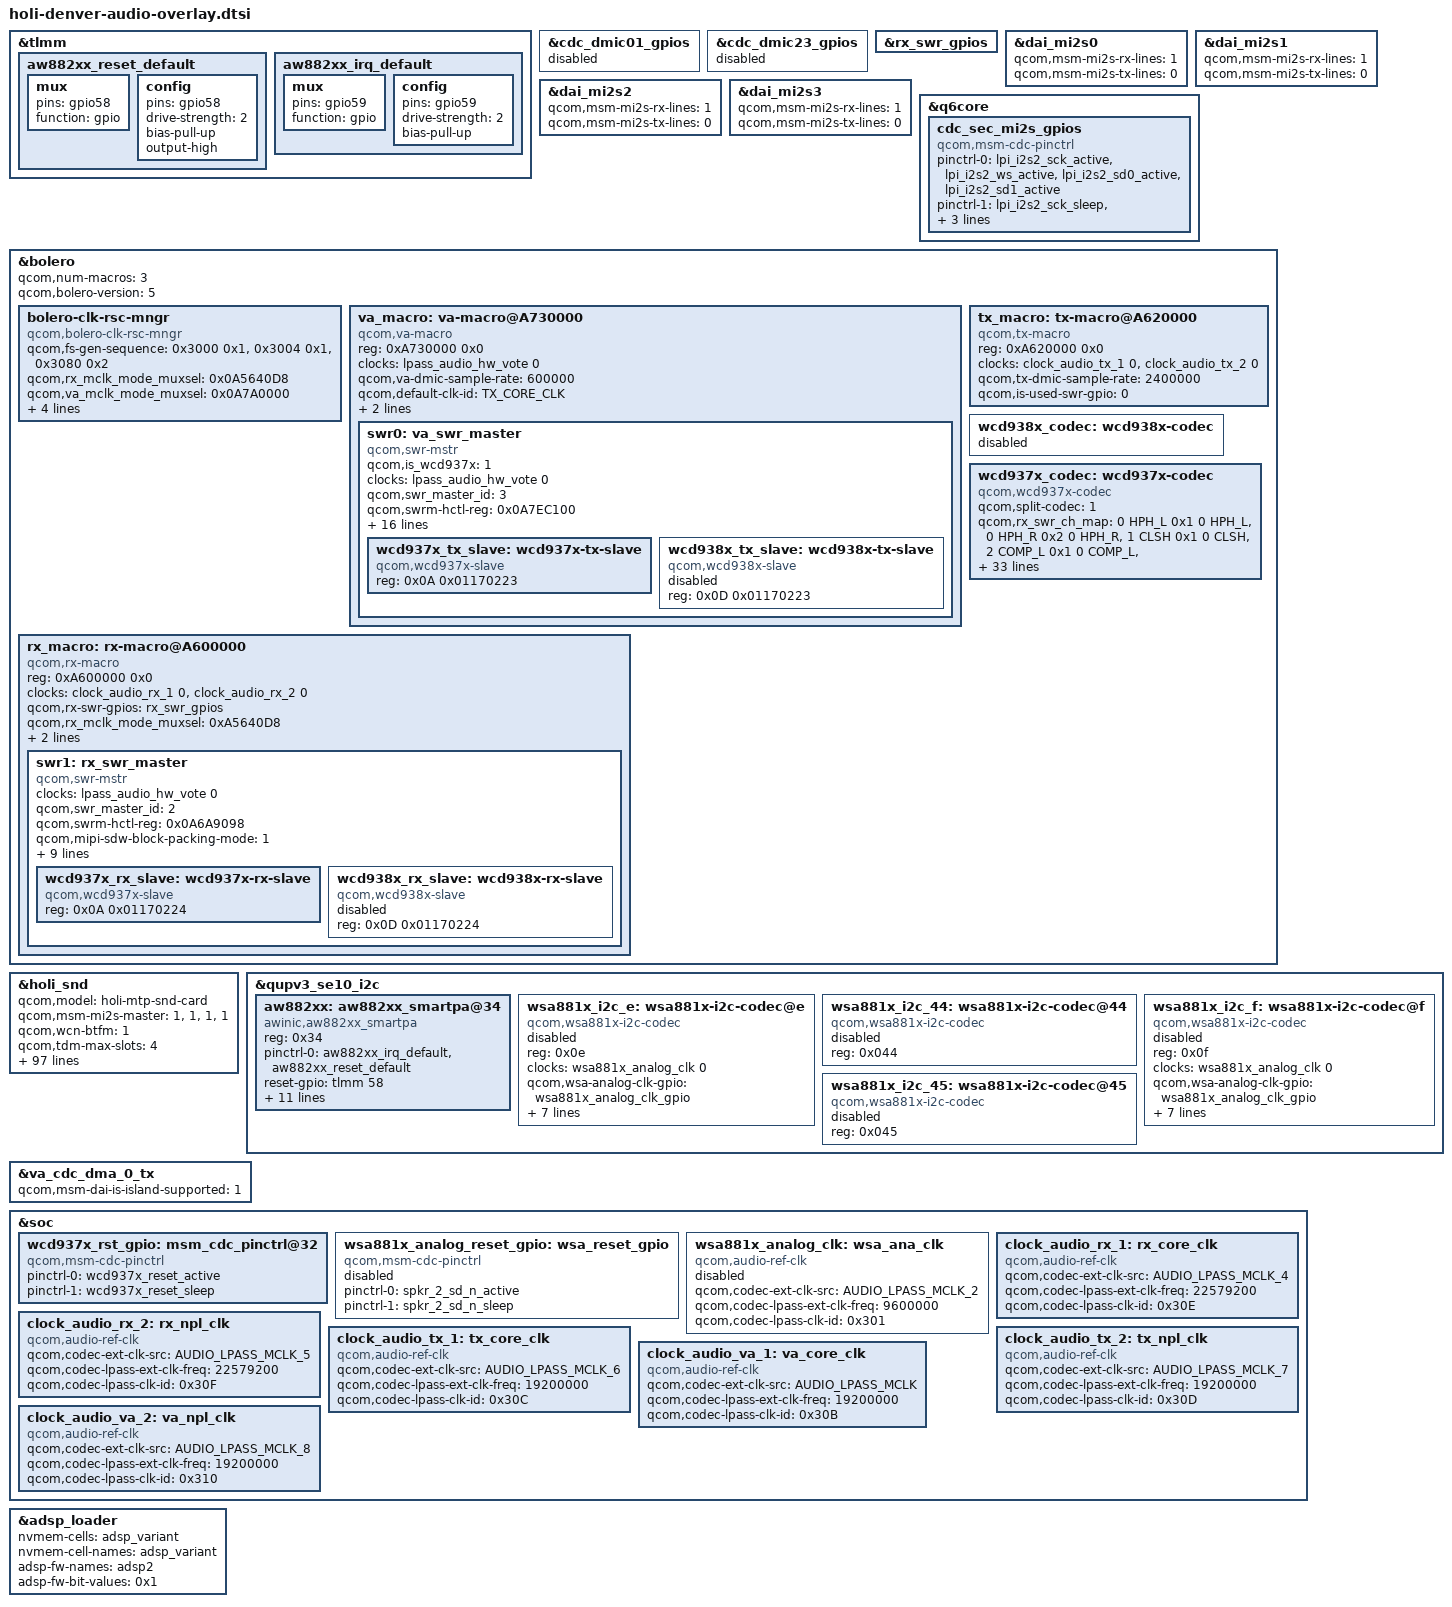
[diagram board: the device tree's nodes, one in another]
#include <dt-bindings/clock/qcom,audio-ext-clk.h>
#include <dt-bindings/sound/qcom,bolero-clk-rsc.h>
#include <dt-bindings/sound/audio-codec-port-types.h>
#include <dt-bindings/interrupt-controller/arm-gic.h>
#include <dt-bindings/gpio/gpio.h>

&tlmm{
	aw882xx_reset_default: aw882xx_reset_default {
		mux {
			pins = "gpio58";
			function = "gpio";
		};
		config {
			pins = "gpio58";
			drive-strength = <2>; /* 2 MA */
			bias-pull-up;
			output-high;
		};
	};

	aw882xx_irq_default: aw882xx_irq_default {
		mux {
			pins = "gpio59";
			function = "gpio";
		};
		config {
			pins = "gpio59";
			drive-strength = <2>; /* 2 MA */
			bias-pull-up;
		};
	};
};

&cdc_dmic01_gpios {
	status = "disabled";
};

&cdc_dmic23_gpios {
	status = "disabled";
};

&rx_swr_gpios {
	status = "okay";
};

&dai_mi2s0 {
	status = "okay";
	qcom,msm-mi2s-rx-lines = <1>;
	qcom,msm-mi2s-tx-lines = <0>;
};

&dai_mi2s1 {
	status = "okay";
	qcom,msm-mi2s-rx-lines = <1>;
	qcom,msm-mi2s-tx-lines = <0>;
};

&dai_mi2s2 {
	status = "okay";
	qcom,msm-mi2s-rx-lines = <1>;
	qcom,msm-mi2s-tx-lines = <0>;
};

&dai_mi2s3 {
	status = "okay";
	qcom,msm-mi2s-rx-lines = <1>;
	qcom,msm-mi2s-tx-lines = <0>;
};


&q6core {
   cdc_sec_mi2s_gpios: cdc_sec_mi2s_gpios {
           compatible = "qcom,msm-cdc-pinctrl";
           pinctrl-names = "aud_active", "aud_sleep";
           pinctrl-0 = <&lpi_i2s2_sck_active &lpi_i2s2_ws_active
                           &lpi_i2s2_sd0_active &lpi_i2s2_sd1_active>;
           pinctrl-1 = <&lpi_i2s2_sck_sleep &lpi_i2s2_ws_sleep
                           &lpi_i2s2_sd0_sleep &lpi_i2s2_sd1_sleep>;
           qcom,lpi-gpios;
   };
};

&bolero {
	qcom,num-macros = <3>;
	qcom,bolero-version = <5>;
	#address-cells = <1>;
	#size-cells = <1>;
	bolero-clk-rsc-mngr {
		compatible = "qcom,bolero-clk-rsc-mngr";
		qcom,fs-gen-sequence = <0x3000 0x1>,
					<0x3004 0x1>, <0x3080 0x2>;
	qcom,rx_mclk_mode_muxsel = <0x0A5640D8>;
	qcom,va_mclk_mode_muxsel = <0x0A7A0000>;
	clock-names = "tx_core_clk", "tx_npl_clk", "rx_core_clk", "rx_npl_clk",
		 "va_core_clk", "va_npl_clk";
	clocks = <&clock_audio_tx_1 0>, <&clock_audio_tx_2 0>,
		<&clock_audio_rx_1 0>, <&clock_audio_rx_2 0>,
		<&clock_audio_va_1 0>, <&clock_audio_va_2 0>;
	};

	va_macro: va-macro@A730000 {
		compatible = "qcom,va-macro";
		reg = <0xA730000 0x0>;
		clock-names = "lpass_audio_hw_vote";
		clocks = <&lpass_audio_hw_vote 0>;
		qcom,va-dmic-sample-rate = <600000>;
		qcom,default-clk-id = <TX_CORE_CLK>;
		qcom,is-used-swr-gpio = <1>;
		qcom,va-swr-gpios = <&va_swr_gpios>;
		swr0: va_swr_master {
			compatible = "qcom,swr-mstr";
			qcom,is_wcd937x = <1>;
			#address-cells = <2>;
			#size-cells = <0>;
			clock-names = "lpass_audio_hw_vote";
			clocks = <&lpass_audio_hw_vote 0>;
			qcom,swr_master_id = <3>;
			qcom,swrm-hctl-reg = <0x0A7EC100>;
			qcom,mipi-sdw-block-packing-mode = <1>;
			swrm-io-base = <0xA740000 0x0>;
			interrupts-extended =
				<&wakegic 5 IRQ_TYPE_LEVEL_HIGH>,
				<&tlmm 128 GPIO_ACTIVE_HIGH>;
			interrupt-names = "swr_master_irq", "swr_wake_irq";
			qcom,swr-num-ports = <3>;
			qcom,swr-port-mapping = <1 SWRM_TX1_CH1 0x1>,
				<1 SWRM_TX1_CH2 0x2>,
				<1 SWRM_TX1_CH3 0x4>, <1 SWRM_TX1_CH4 0x8>,
				<2 SWRM_TX2_CH1 0x1>, <2 SWRM_TX2_CH2 0x2>,
				<2 SWRM_TX2_CH3 0x4>, <2 SWRM_TX2_CH4 0x8>,
				<3 SWRM_TX3_CH1 0x1>, <3 SWRM_TX3_CH2 0x2>,
				<3 SWRM_TX3_CH3 0x4>, <3 SWRM_TX3_CH4 0x8>;
			qcom,swr-num-dev = <1>;
			qcom,swr-clock-stop-mode0 = <1>;
			qcom,swr-mstr-irq-wakeup-capable = <1>;
			wcd937x_tx_slave: wcd937x-tx-slave {
				compatible = "qcom,wcd937x-slave";
				reg = <0x0A 0x01170223>;
			};

			wcd938x_tx_slave: wcd938x-tx-slave {
				status = "disabled";
				compatible = "qcom,wcd938x-slave";
				reg = <0x0D 0x01170223>;
			};

		};
	};

	tx_macro: tx-macro@A620000 {
		compatible = "qcom,tx-macro";
		reg = <0xA620000 0x0>;
		clock-names = "tx_core_clk", "tx_npl_clk";
		clocks = <&clock_audio_tx_1 0>,
			 <&clock_audio_tx_2 0>;
		qcom,tx-dmic-sample-rate = <2400000>;
		qcom,is-used-swr-gpio = <0>;
	};

	rx_macro: rx-macro@A600000 {
		compatible = "qcom,rx-macro";
		reg = <0xA600000 0x0>;
		clock-names = "rx_core_clk", "rx_npl_clk";
		clocks = <&clock_audio_rx_1 0>,
			 <&clock_audio_rx_2 0>;
		qcom,rx-swr-gpios = <&rx_swr_gpios>;
		qcom,rx_mclk_mode_muxsel = <0xA5640D8>;
		qcom,rx-bcl-pmic-params = /bits/ 8 <0x00 0x03 0x48>;
		qcom,default-clk-id = <TX_CORE_CLK>;
		swr1: rx_swr_master {
			compatible = "qcom,swr-mstr";
			#address-cells = <2>;
			#size-cells = <0>;
			clock-names = "lpass_audio_hw_vote";
			clocks = <&lpass_audio_hw_vote 0>;
			qcom,swr_master_id = <2>;
			qcom,swrm-hctl-reg = <0x0A6A9098>;
			qcom,mipi-sdw-block-packing-mode = <1>;
			swrm-io-base = <0xA610000 0x0>;
			interrupts = <GIC_SPI 297 IRQ_TYPE_LEVEL_HIGH>;
			interrupt-names = "swr_master_irq";
			qcom,swr-num-ports = <6>;
			qcom,swr-port-mapping = <1 HPH_L 0x1>,
				<1 HPH_R 0x2>, <2 CLSH 0x1>,
				<3 COMP_L 0x1>, <3 COMP_R 0x2>,
				<4 LO 0x1>, <5 DSD_L 0x1>,
				<5 DSD_R 0x2>, <6 PCM_OUT1 0x01>;
			qcom,swr-num-dev = <1>;
			qcom,swr-clock-stop-mode0 = <1>;
			wcd937x_rx_slave: wcd937x-rx-slave {
				compatible = "qcom,wcd937x-slave";
				reg = <0x0A 0x01170224>;
			};

			wcd938x_rx_slave: wcd938x-rx-slave {
				status = "disabled";
				compatible = "qcom,wcd938x-slave";
				reg = <0x0D 0x01170224>;
			};
		};
	};

	wcd938x_codec: wcd938x-codec {
		status = "disabled";
	};

	wcd937x_codec: wcd937x-codec {
		compatible = "qcom,wcd937x-codec";
		qcom,split-codec = <1>;
		qcom,rx_swr_ch_map = <0 HPH_L 0x1 0 HPH_L>,
			<0 HPH_R 0x2 0 HPH_R>, <1 CLSH 0x1 0 CLSH>,
			<2 COMP_L 0x1 0 COMP_L>, <2 COMP_R 0x2 0 COMP_R>,
			<3 LO 0x1 0 LO>, <4 DSD_L 0x1 0 DSD_L>,
			<4 DSD_R 0x2 0 DSD_R>;
		qcom,tx_swr_ch_map = <0 ADC1 0x1 0 SWRM_TX1_CH1>,
			<1 ADC2 0x1 0 SWRM_TX2_CH1>,
			<1 ADC3 0x2 0 SWRM_TX2_CH2>,
			<2 DMIC0 0x1 0 SWRM_TX1_CH4>,
			<2 DMIC1 0x2 0 SWRM_TX2_CH1>,
			<2 MBHC 0x4 0 SWRM_TX2_CH2>,
			<3 DMIC2 0x1 0 SWRM_TX2_CH3>,
			<3 DMIC3 0x2 0 SWRM_TX2_CH4>,
			<3 DMIC4 0x4 0 SWRM_TX3_CH1>,
			<3 DMIC5 0x8 0 SWRM_TX3_CH2>;

		qcom,wcd-rst-gpio-node = <&wcd937x_rst_gpio>;
		qcom,rx-slave = <&wcd937x_rx_slave>;
		qcom,tx-slave = <&wcd937x_tx_slave>;

		cdc-vdd-rxtx-supply = <&L11A>;
		qcom,cdc-vdd-rxtx-voltage = <1800000 1800000>;
		qcom,cdc-vdd-rxtx-current = <30000>;

		cdc-vddpx-supply = <&L11A>;
		qcom,cdc-vddpx-voltage = <1800000 1800000>;
		qcom,cdc-vddpx-current = <30000>;

		cdc-vdd-buck-supply = <&L14A>;
		qcom,cdc-vdd-buck-voltage = <1800000 1800000>;
		qcom,cdc-vdd-buck-current = <650000>;

		cdc-vdd-mic-bias-supply = <&BOB>;
		qcom,cdc-vdd-mic-bias-voltage = <3296000 3296000>;
		qcom,cdc-vdd-mic-bias-current = <45000>;

		qcom,cdc-micbias1-mv = <1800>;
		qcom,cdc-micbias2-mv = <1800>;
		qcom,cdc-micbias3-mv = <1800>;

		qcom,cdc-static-supplies = "cdc-vdd-rxtx",
					   "cdc-vddpx",
					   "cdc-vdd-mic-bias";
		qcom,cdc-on-demand-supplies = "cdc-vdd-buck";
	};
};

&holi_snd {
	qcom,model = "holi-mtp-snd-card";
	qcom,msm-mi2s-master = <1>, <1>, <1>, <1>;
	qcom,wcn-btfm = <1>;
	qcom,tdm-max-slots = <4>;
	qcom,sec-mi2s-gpios = <&cdc_sec_mi2s_gpios>;

		asoc-platform = <&pcm0>, <&pcm1>, <&pcm2>, <&voip>, <&voice>,
				<&loopback>, <&compress>, <&hostless>,
				<&afe>, <&lsm>, <&routing>, <&compr>,
				<&pcm_noirq>;
		asoc-platform-names = "msm-pcm-dsp.0", "msm-pcm-dsp.1",
				"msm-pcm-dsp.2", "msm-voip-dsp",
				"msm-pcm-voice", "msm-pcm-loopback",
				"msm-compress-dsp", "msm-pcm-hostless",
				"msm-pcm-afe", "msm-lsm-client",
				"msm-pcm-routing", "msm-compr-dsp",
				"msm-pcm-dsp-noirq";
		asoc-cpu = <&dai_mi2s0>, <&dai_mi2s1>,
				<&dai_mi2s2>, <&dai_mi2s3>,
				<&dai_pri_auxpcm>,
				<&dai_sec_auxpcm>, <&dai_tert_auxpcm>,
				<&dai_quat_auxpcm>,
				<&afe_pcm_rx>, <&afe_pcm_tx>, <&afe_proxy_rx>,
				<&afe_proxy_tx>, <&incall_record_rx>,
				<&incall_record_tx>, <&incall_music_rx>,
				<&incall_music_2_rx>,
				<&afe_proxy_tx_1>,
				<&proxy_rx>, <&proxy_tx>,
				<&usb_audio_rx>, <&usb_audio_tx>,
				<&sb_7_rx>, <&sb_7_tx>, <&sb_8_tx>,
				<&dai_pri_tdm_rx_0>, <&dai_pri_tdm_tx_0>,
				<&dai_sec_tdm_rx_0>, <&dai_sec_tdm_tx_0>,
				<&dai_tert_tdm_rx_0>, <&dai_tert_tdm_tx_0>,
				<&dai_quat_tdm_rx_0>, <&dai_quat_tdm_tx_0>,
				<&va_cdc_dma_0_tx>, <&va_cdc_dma_1_tx>,
				<&va_cdc_dma_2_tx>,
				<&rx_cdc_dma_0_rx>, <&tx_cdc_dma_0_tx>,
				<&rx_cdc_dma_1_rx>, <&tx_cdc_dma_1_tx>,
				<&rx_cdc_dma_2_rx>, <&tx_cdc_dma_2_tx>,
				<&rx_cdc_dma_3_rx>, <&tx_cdc_dma_3_tx>,
				<&rx_cdc_dma_4_rx>, <&tx_cdc_dma_4_tx>,
				<&rx_cdc_dma_5_rx>, <&tx_cdc_dma_5_tx>,
				<&rx_cdc_dma_7_rx>,<&afe_loopback_tx>;
		asoc-cpu-names = "msm-dai-q6-mi2s.0", "msm-dai-q6-mi2s.1",
				"msm-dai-q6-mi2s.2", "msm-dai-q6-mi2s.3",
				"msm-dai-q6-auxpcm.1",
				"msm-dai-q6-auxpcm.2", "msm-dai-q6-auxpcm.3",
				"msm-dai-q6-auxpcm.4",
				"msm-dai-q6-dev.224",
				"msm-dai-q6-dev.225", "msm-dai-q6-dev.241",
				"msm-dai-q6-dev.240", "msm-dai-q6-dev.32771",
				"msm-dai-q6-dev.32772", "msm-dai-q6-dev.32773",
				"msm-dai-q6-dev.32770",
				"msm-dai-q6-dev.242",
				"msm-dai-q6-dev.8194", "msm-dai-q6-dev.8195",
				"msm-dai-q6-dev.28672", "msm-dai-q6-dev.28673",
				"msm-dai-q6-dev.16398", "msm-dai-q6-dev.16399",
				"msm-dai-q6-dev.16401",
				"msm-dai-q6-tdm.36864", "msm-dai-q6-tdm.36865",
				"msm-dai-q6-tdm.36880", "msm-dai-q6-tdm.36881",
				"msm-dai-q6-tdm.36896", "msm-dai-q6-tdm.36897",
				"msm-dai-q6-tdm.36912", "msm-dai-q6-tdm.36913",
				"msm-dai-cdc-dma-dev.45089",
				"msm-dai-cdc-dma-dev.45091",
				"msm-dai-cdc-dma-dev.45093",
				"msm-dai-cdc-dma-dev.45104",
				"msm-dai-cdc-dma-dev.45105",
				"msm-dai-cdc-dma-dev.45106",
				"msm-dai-cdc-dma-dev.45107",
				"msm-dai-cdc-dma-dev.45108",
				"msm-dai-cdc-dma-dev.45109",
				"msm-dai-cdc-dma-dev.45110",
				"msm-dai-cdc-dma-dev.45111",
				"msm-dai-cdc-dma-dev.45112",
				"msm-dai-cdc-dma-dev.45113",
				"msm-dai-cdc-dma-dev.45114",
				"msm-dai-cdc-dma-dev.45115",
				"msm-dai-cdc-dma-dev.45118",
				"msm-dai-q6-dev.24577";


	qcom,audio-routing =
		"AMIC1", "Analog Mic1",
		"Analog Mic1", "MIC BIAS1",
		"AMIC2", "Analog Mic2",
		"Analog Mic2", "MIC BIAS2",
		"AMIC3", "Analog Mic3",
		"Analog Mic3", "MIC BIAS3",
		"Analog Mic4", "MIC BIAS3",
		"TX DMIC0", "Digital Mic0",
		"TX DMIC0", "MIC BIAS1",
		"TX DMIC1", "Digital Mic1",
		"TX DMIC1", "MIC BIAS1",
		"TX DMIC2", "Digital Mic2",
		"TX DMIC2", "MIC BIAS3",
		"TX DMIC3", "Digital Mic3",
		"TX DMIC3", "MIC BIAS3",
		"IN1_HPHL", "HPHL_OUT",
		"IN2_HPHR", "HPHR_OUT",
		"IN3_AUX", "AUX_OUT",
		"RX_TX DEC0_INP", "TX DEC0 MUX",
		"RX_TX DEC1_INP", "TX DEC1 MUX",
		"RX_TX DEC2_INP", "TX DEC2 MUX",
		"RX_TX DEC3_INP", "TX DEC3 MUX",
		"TX SWR_INPUT", "WCD_TX_OUTPUT",
		"VA SWR_INPUT", "VA_SWR_CLK",
		"VA SWR_INPUT", "WCD_TX_OUTPUT",
		"VA_AIF1 CAP", "VA_SWR_CLK",
		"VA_AIF2 CAP", "VA_SWR_CLK",
		"VA_AIF3 CAP", "VA_SWR_CLK",
		"VA DMIC0", "Digital Mic0",
		"VA DMIC1", "Digital Mic1",
		"VA DMIC2", "Digital Mic2",
		"VA DMIC3", "Digital Mic3",
		"VA DMIC4", "Digital Mic4",
		"VA DMIC5", "Digital Mic5",
		"VA DMIC0", "VA MIC BIAS1",
		"VA DMIC1", "VA MIC BIAS1",
		"VA DMIC2", "VA MIC BIAS3",
		"VA DMIC3", "VA MIC BIAS3";
	qcom,msm-mbhc-hphl-swh = <1>;
	qcom,msm-mbhc-gnd-swh = <1>;
	asoc-codec  = <&stub_codec>, <&bolero>,
		      <&wcd937x_codec>,<&aw882xx>;
	asoc-codec-names = "msm-stub-codec.1", "bolero_codec",
			   "wcd937x_codec", "aw882xx_codec";
	qcom,msm_audio_ssr_devs = <&audio_apr>, <&q6core>, <&lpi_tlmm>,
				  <&bolero>;
};

&qupv3_se10_i2c {
        status = "ok";
        aw882xx: aw882xx_smartpa@34 {
			compatible = "awinic,aw882xx_smartpa";
			reg = <0x34>;
			pinctrl-names = "default";
			pinctrl-0 = <&aw882xx_irq_default>, <&aw882xx_reset_default>;
			reset-gpio = <&tlmm 58 0>;
			irq-gpio = <&tlmm 59 0x2008>;
			monitor-flag = <1>;
			monitor-timer-val = <3000>;
			afe-rx-portid = <0x1002>;
			afe-tx-portid = <0x1003>;
			low-vol-table-down = <3650 9 3 3750 9 2 3900 9 1>;
			low-vol-table-up = <4000 9 0 3800 9 1 3700 9 2>;
			low-temp-table-down = <0xFFFFFFFB 0x4 0x10 0xFFBEAE7E 0x0 0x5 0x9 0xFFD80505 0x5 0x6 0x6 0xFFED714D>;
			low-temp-table-up = <0x7 0x9 0x0 0x00000000 0x2 0x6 0x06 0xFFED714D 0xFFFFFFE 0x05 0x09 0xFFD80505>;
			status = "okay";
		};
		
	wsa881x_i2c_e: wsa881x-i2c-codec@e {
		status = "disabled";	
		compatible = "qcom,wsa881x-i2c-codec";
		reg = <0x0e>;
		clock-names = "wsa_mclk";
		clocks = <&wsa881x_analog_clk 0>;
		qcom,wsa-analog-clk-gpio = <&wsa881x_analog_clk_gpio>;
		qcom,wsa-analog-reset-gpio = <&wsa881x_analog_reset_gpio>;
		cdc-vdd-1p8-supply = <&L11A>;
		qcom,cdc-vdd-1p8-voltage = <1800000 1800000>;
		qcom,cdc-vdd-1p8-current = <10000>;
		qcom,cdc-static-supplies = "cdc-vdd-1p8";
		qcom,wsa-prefix = "SpkrMono";
	};

	wsa881x_i2c_44: wsa881x-i2c-codec@44 {
		status = "disabled";	
		compatible = "qcom,wsa881x-i2c-codec";
		reg = <0x044>;
	};

	wsa881x_i2c_f: wsa881x-i2c-codec@f {
		status = "disabled";
		compatible = "qcom,wsa881x-i2c-codec";
		reg = <0x0f>;
		clock-names = "wsa_mclk";
		clocks = <&wsa881x_analog_clk 0>;
		qcom,wsa-analog-clk-gpio = <&wsa881x_analog_clk_gpio>;
		qcom,wsa-analog-reset-gpio = <&wsa881x_analog_reset_gpio>;
		cdc-vdd-1p8-supply = <&L11A>;
		qcom,cdc-vdd-1p8-voltage = <1800000 1800000>;
		qcom,cdc-vdd-1p8-current = <10000>;
		qcom,cdc-static-supplies = "cdc-vdd-1p8";
		qcom,wsa-prefix = "SpkrMono";
	};

	wsa881x_i2c_45: wsa881x-i2c-codec@45 {
		status = "disabled";
		compatible = "qcom,wsa881x-i2c-codec";
		reg = <0x045>;
	};
		
};

&va_cdc_dma_0_tx {
	qcom,msm-dai-is-island-supported = <1>;
};

&soc {
	wcd937x_rst_gpio: msm_cdc_pinctrl@32 {
		compatible = "qcom,msm-cdc-pinctrl";
		pinctrl-names = "aud_active", "aud_sleep";
		pinctrl-0 = <&wcd937x_reset_active>;
		pinctrl-1 = <&wcd937x_reset_sleep>;
	};

	wsa881x_analog_reset_gpio: wsa_reset_gpio {
		status = "disabled";	
		compatible = "qcom,msm-cdc-pinctrl";
		pinctrl-names = "aud_active", "aud_sleep";
		pinctrl-0 = <&spkr_2_sd_n_active>;
		pinctrl-1 = <&spkr_2_sd_n_sleep>;
		#gpio-cells = <0>;
	};

	wsa881x_analog_clk: wsa_ana_clk {
		status = "disabled";	
		compatible = "qcom,audio-ref-clk";
		qcom,codec-ext-clk-src = <AUDIO_LPASS_MCLK_2>;
		qcom,codec-lpass-ext-clk-freq = <9600000>;
		qcom,codec-lpass-clk-id = <0x301>;
		#clock-cells = <1>;
	};

	clock_audio_rx_1: rx_core_clk {
		compatible = "qcom,audio-ref-clk";
		qcom,codec-ext-clk-src = <AUDIO_LPASS_MCLK_4>;
		qcom,codec-lpass-ext-clk-freq = <22579200>;
		qcom,codec-lpass-clk-id = <0x30E>;
		#clock-cells = <1>;
	};

	clock_audio_rx_2: rx_npl_clk {
		compatible = "qcom,audio-ref-clk";
		qcom,codec-ext-clk-src = <AUDIO_LPASS_MCLK_5>;
		qcom,codec-lpass-ext-clk-freq = <22579200>;
		qcom,codec-lpass-clk-id = <0x30F>;
		#clock-cells = <1>;
	};

	clock_audio_tx_1: tx_core_clk {
		compatible = "qcom,audio-ref-clk";
		qcom,codec-ext-clk-src = <AUDIO_LPASS_MCLK_6>;
		qcom,codec-lpass-ext-clk-freq = <19200000>;
		qcom,codec-lpass-clk-id = <0x30C>;
		#clock-cells = <1>;
	};

	clock_audio_tx_2: tx_npl_clk {
		compatible = "qcom,audio-ref-clk";
		qcom,codec-ext-clk-src = <AUDIO_LPASS_MCLK_7>;
		qcom,codec-lpass-ext-clk-freq = <19200000>;
		qcom,codec-lpass-clk-id = <0x30D>;
		#clock-cells = <1>;
	};

	clock_audio_va_1: va_core_clk {
		compatible = "qcom,audio-ref-clk";
		qcom,codec-ext-clk-src = <AUDIO_LPASS_MCLK>;
		qcom,codec-lpass-ext-clk-freq = <19200000>;
		qcom,codec-lpass-clk-id = <0x30B>;
		#clock-cells = <1>;
	};

	clock_audio_va_2: va_npl_clk {
		compatible = "qcom,audio-ref-clk";
		qcom,codec-ext-clk-src = <AUDIO_LPASS_MCLK_8>;
		qcom,codec-lpass-ext-clk-freq = <19200000>;
		qcom,codec-lpass-clk-id = <0x310>;
		#clock-cells = <1>;
	};
};

&adsp_loader {
	nvmem-cells = <&adsp_variant>;
	nvmem-cell-names = "adsp_variant";
	adsp-fw-names = "adsp2";
	adsp-fw-bit-values = <0x1>;
};
